# toyperiph register map
Registers are 32-bit, read-write, reset 0x0 unless marked. A register's access mark holds for its fields unless they carry their own. Offsets are from the block's base; lines under a group give offsets from that group; [hi:lo] are bit positions; {n}, {i} and the like mark numbered series; 'fields as' and 'values as' point back to an identical list; <NAME> marks a mode.

## Memory map
0x40000000 TOYPERIPH

## TOYPERIPH
Base 0x40000000
0x00 GPIO_OUT — GPIO output
  [7:0] OUT — Output level of pins 0-7.
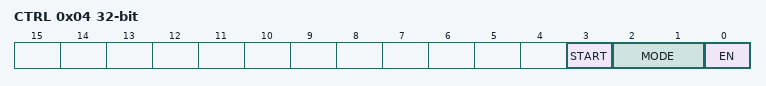
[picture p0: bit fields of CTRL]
0x04 CTRL — Control
  [3] START — Write 1 to start a calibration; hardware clears it when the calibration is done.
  [2:1] MODE — Operating mode: 0 idle, 1 run, 2 step, 3 test.
  [0] EN — Enable the peripheral.
0x08 STATUS
  [0] DONE write-1-clears — Set by hardware when an operation completes; write 1 to clear.
0x0C CMD wo — Command
  [0] GO — Write 1 to start one operation; reads as 0 (clears itself after one cycle).
0x10 COUNT ro — Counter
  [15:0] COUNT — Operations completed since reset.
